# CS32F030x register map
File version: 1.0
Registers are 32-bit, read-write, reset 0x0 unless marked. A register's access mark holds for its fields unless they carry their own. Offsets are from the block's base; [hi:lo] are bit positions; {n}, {i} and the like mark numbered series; 'fields as' and 'values as' point back to an identical list.

## DMA — DMA controller
Base 0x40020000
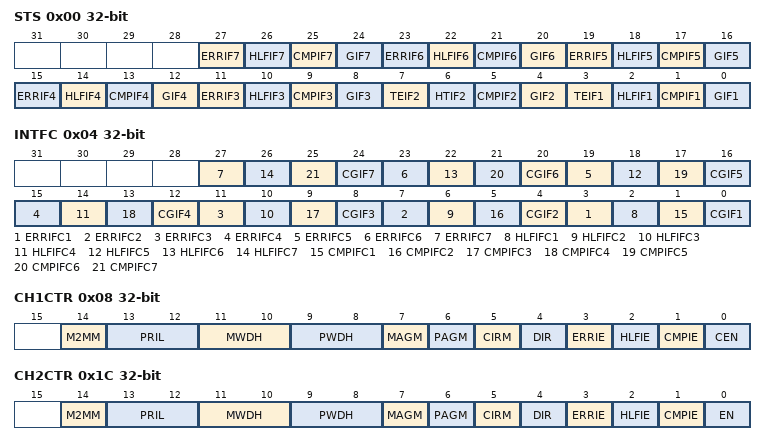
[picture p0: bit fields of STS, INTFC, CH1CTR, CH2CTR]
0x00 STS ro — DMA interrupt status register
  [4n-1] ERRIF{n} (n=3..7) — Transfer error flag of Channel {n}
  [4n-2] HLFIF{n} (n=3..7) — Half transfer flag of Channel {n}
  [4n-3] CMPIF{n} (n=1..7) — Transfer complete flag of Channel {n}
  [4n-4] GIF{n} (n=1..7) — Global interrupt flag of Channel {n}
  [7] TEIF2 — Transfer error flag of Channel 2
  [6] HTIF2 — Half transfer flag of Channel 2
  [3] TEIF1 — Transfer error flag of Channel 1
  [2] HLFIF1 — Half transfer flag of Channel 1
0x04 INTFC wo — DMA interrupt status clear register
  [4n-1] ERRIFC{n} (n=1..7) — Transfer error flag clear of Channel {n}
  [4n-2] HLFIFC{n} (n=1..7) — Half transfer flag clear of Channel {n}
  [4n-3] CMPIFC{n} (n=1..7) — Transfer complete flag clear of Channel {n}
  [4n-4] CGIF{n} (n=1..7) — Global interrupt flag clear of Channel {n}
0x08 CH1CTR — DMA channel 1 controller register
  [14] M2MM — Memory to memory mode
  [13:12] PRIL — Priority level of Channel
  [11:10] MWDH — Memory width
  [9:8] PWDH — Peripheral width
  [7] MAGM — Memory address generation mode
  [6] PAGM — Peripheral address generation mode
  [5] CIRM — Circular mode
  [4] DIR — Direction of transfer
  [3] ERRIE — Enable bit for Transfer error interrupt
  [2] HLFIE — Enable bit for Half transfer interrupt
  [1] CMPIE — Enable bit for Transfer complete interrupt
  [0] CEN — Channel enable
0x0C CH1NUM — Transfer data number register of DMA channel 1
  [15:0] NUM — transfer data number
0x10 CH1PA — Peripheral address register of DMA channel 1
  [31:0] PADR — Peripheral address
{0x0+0x14*i} CH{i}MA (i=1..7) — Memory address register of DMA channel {i}
  [31:0] MADR — Memory address
0x1C CH2CTR — DMA channel 2 controller register
  [14] M2MM — Memory to memory mode
  [13:12] PRIL — Priority level of Channel
  [11:10] MWDH — Memory width
  [9:8] PWDH — Peripheral width
  [7] MAGM — Memory address generation mode
  [6] PAGM — Peripheral address generation mode
  [5] CIRM — Circular mode
  [4] DIR — Direction of transfer
  [3] ERRIE — Enable bit for Transfer error interrupt
  [2] HLFIE — Enable bit for Half transfer interrupt
  [1] CMPIE — Enable bit for Transfer complete interrupt
  [0] EN — Channel enable
0x20 CH2NUM — Transfer data number register of DMA channel 2
  [15:0] NUM — transfer data number
0x24 CH2PA — Peripheral address register of DMA channel 2
  [31:0] PADR — Peripheral address
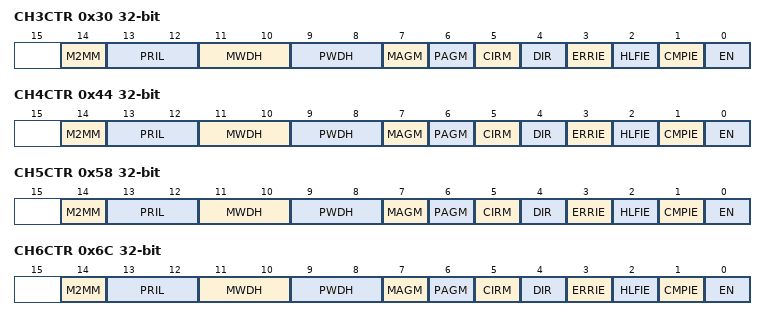
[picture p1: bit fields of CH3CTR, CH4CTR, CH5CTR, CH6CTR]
0x30 CH3CTR — DMA channel 3 controller register
  fields as CH2CTR
0x34 CH3NUM — Transfer data number register of DMA channel 3
  [15:0] NUM — transfer data number
0x38 CH3PA — Peripheral address register of DMA channel 3
  [31:0] PADR — Peripheral address
0x44 CH4CTR — DMA channel 4 controller register
  fields as CH2CTR
0x48 CH4NUM — Transfer data number register of DMA channel 4
  [15:0] NUM — transfer data number
0x4C CH4PA — Peripheral address register of DMA channel 4
  [31:0] PADR — Peripheral address
0x58 CH5CTR — DMA channel 5 controller register
  fields as CH2CTR
0x5C CH5NUM — Transfer data number register of DMA channel 5
  [15:0] NUM — transfer data number
0x60 CH5PA — Peripheral address register of DMA channel 5
  [31:0] PADR — Peripheral address
0x6C CH6CTR — DMA channel 6 controller register
  fields as CH2CTR
0x70 CH6NUM — Transfer data number register of DMA channel 7
  [15:0] NUM — transfer data number
0x74 CH6PA — Peripheral address register of DMA channel 6
  [31:0] PADR — Peripheral address
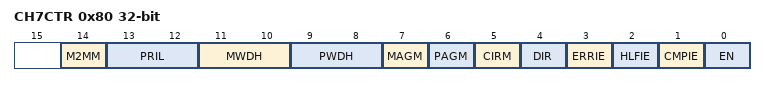
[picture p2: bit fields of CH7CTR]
0x80 CH7CTR — DMA channel 7 controller register
  fields as CH2CTR
0x84 CH7NUM — Transfer data number register of DMA channel 7
  [15:0] NUM — transfer data number
0x88 CH7PA — Peripheral address register of DMA channel 7
  [31:0] PADR — Peripheral address

## SYSCFG — System configuration
Base 0x40010000
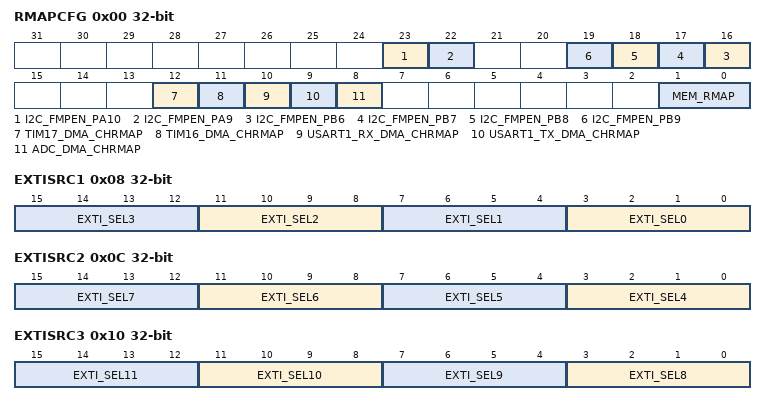
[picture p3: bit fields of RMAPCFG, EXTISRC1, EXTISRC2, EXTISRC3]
0x00 RMAPCFG — SYSCFG remap configuration
  [23] I2C_FMPEN_PA10 — Fast Mode Plus (FM+) driving capability activation bits.
  [22] I2C_FMPEN_PA9 — Fast Mode Plus (FM+) driving capability activation bits.
  [n+10] I2C_FMPEN_PB{n} (n=6..9) — Fast Mode Plus (FM+) driving capability activation bits.
  [12] TIM17_DMA_CHRMAP — TIM17 DMA channel remapping
  [11] TIM16_DMA_CHRMAP — TIM16 DMA channel remapping
  [10] USART1_RX_DMA_CHRMAP — USART1 RX DMA channel remapping
  [9] USART1_TX_DMA_CHRMAP — USART1 TX DMA channel remapping
  [8] ADC_DMA_CHRMAP — ADC DMA channel remapping
  [1:0] MEM_RMAP — Memory remapping selection
0x08 EXTISRC1 — external interrupt source selection register 1
  [4n+3:4n] EXTI_SEL{n} (n=0..3) — External interrupt source selection {n}
0x0C EXTISRC2 — external interrupt source selection register 2
  [4n-13:4n-16] EXTI_SEL{n} (n=4..7) — External interrupt source selection {n}
0x10 EXTISRC3 — external interrupt source selection register 3
  [4n-29:4n-32] EXTI_SEL{n} (n=8..11) — External interrupt source selection {n}
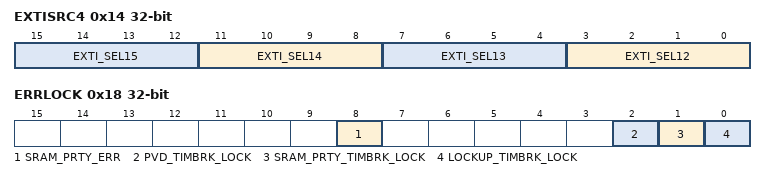
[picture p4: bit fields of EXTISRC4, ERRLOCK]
0x14 EXTISRC4 — external interrupt source selection register 4
  [4n-45:4n-48] EXTI_SEL{n} (n=12..15) — External interrupt source selection {n}
0x18 ERRLOCK — error and timer break lock
  [8] SRAM_PRTY_ERR — SRAM parity error flag
  [2] PVD_TIMBRK_LOCK — PVD output lock to tim break enable
  [1] SRAM_PRTY_TIMBRK_LOCK — SRAM parity lock to tim break
  [0] LOCKUP_TIMBRK_LOCK — Cortex-M0 LOCKUP lock to tim break enable
